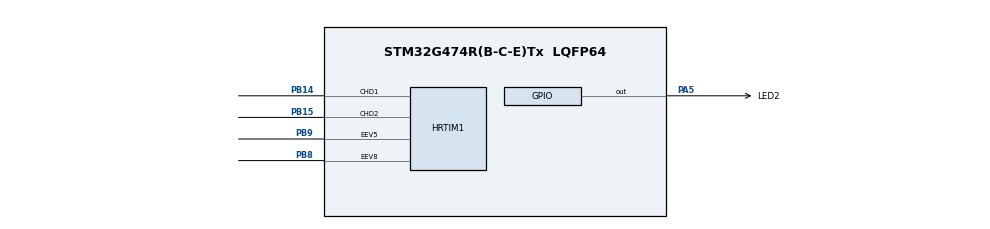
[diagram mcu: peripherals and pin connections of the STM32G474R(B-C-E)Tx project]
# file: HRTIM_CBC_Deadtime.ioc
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HRTIM1.ADCTrigger_Id1=__NULL
HRTIM1.ADCTrigger_Id10=__NULL
HRTIM1.ADCTrigger_Id2=__NULL
HRTIM1.ADCTrigger_Id3=__NULL
HRTIM1.ADCTrigger_Id4=__NULL
HRTIM1.ADCTrigger_Id5=__NULL
HRTIM1.ADCTrigger_Id6=__NULL
HRTIM1.ADCTrigger_Id7=__NULL
HRTIM1.ADCTrigger_Id8=__NULL
HRTIM1.ADCTrigger_Id9=__NULL
HRTIM1.AutoDelayedMode2-Output_TD1TD2=HRTIM_AUTODELAYEDMODE_AUTODELAYED_TIMEOUTCMP3
HRTIM1.AutoDelayedMode4-Output_TD1TD2=HRTIM_AUTODELAYEDMODE_AUTODELAYED_NOTIMEOUT
HRTIM1.BurstDMAconfig-Output_TD1TD2=__NULL
HRTIM1.BurstMode-Output_TD1TD2=HRTIM_TIMERBURSTMODE_MAINTAINCLOCK
HRTIM1.BurstModeEntryDelayed1-Output_TD1TD2=HRTIM_OUTPUTBURSTMODEENTRY_REGULAR
HRTIM1.BurstModeEntryDelayed2-Output_TD1TD2=HRTIM_OUTPUTBURSTMODEENTRY_REGULAR
HRTIM1.CaptureUnit1-Output_TD1TD2=HRTIM_CAPTUREUNIT_1
HRTIM1.CaptureUnit2-Output_TD1TD2=HRTIM_CAPTUREUNIT_2
HRTIM1.ChopperModeEnable1-Output_TD1TD2=HRTIM_OUTPUTCHOPPERMODE_DISABLED
HRTIM1.ChopperModeEnable2-Output_TD1TD2=HRTIM_OUTPUTCHOPPERMODE_DISABLED
HRTIM1.ChopperModeconfig-Output_TD1TD2=__NULL
HRTIM1.CompareUnit1-Output_TD1TD2=HRTIM_COMPAREUNIT_1
HRTIM1.CompareUnit2-Output_TD1TD2=HRTIM_COMPAREUNIT_2
HRTIM1.CompareUnit3-Output_TD1TD2=HRTIM_COMPAREUNIT_3
HRTIM1.CompareUnit4-Output_TD1TD2=HRTIM_COMPAREUNIT_4
HRTIM1.CompareValue1-Output_TD1TD2=DEADTIME
HRTIM1.CompareValue2-Output_TD1TD2=DEADTIME
HRTIM1.CompareValue4-Output_TD1TD2=DEADTIME
HRTIM1.Configuration_TD=Waveform
HRTIM1.DACSynchro-Output_TD1TD2=HRTIM_DACSYNC_NONE
HRTIM1.DeadTimeInsertion-Output_TD1TD2=HRTIM_TIMDEADTIMEINSERTION_DISABLED
HRTIM1.Deadtimeconfig-Output_TD1TD2=__NULL
HRTIM1.DelayedProtectionMode-Output_TD1TD2=HRTIM_TIMER_D_E_DELAYEDPROTECTION_DISABLED
HRTIM1.DualChannelDacEnableFake_TD-Output_TD1TD2=HRTIM_TIMER_DCDE_DISABLED
HRTIM1.Enable=HRTIM_BURSTMODECTL_DISABLED
HRTIM1.Event1-Output_TD1TD2=__NULL
HRTIM1.Event10-Output_TD1TD2=__NULL
HRTIM1.Event2-Output_TD1TD2=__NULL
HRTIM1.Event3-Output_TD1TD2=__NULL
HRTIM1.Event4-Output_TD1TD2=__NULL
HRTIM1.Event5-Output_TD1TD2=__NULL
HRTIM1.Event6-Output_TD1TD2=__NULL
HRTIM1.Event7-Output_TD1TD2=__NULL
HRTIM1.Event8-Output_TD1TD2=HRTIM_EVENT_8
HRTIM1.Event9-Output_TD1TD2=__NULL
HRTIM1.EventEnableA-Output_TD1TD2=__NULL
HRTIM1.EventPrescaler=HRTIM_EVENTPRESCALER_DIV1
HRTIM1.Event_EEV1=__NULL
HRTIM1.Event_EEV10=__NULL
HRTIM1.Event_EEV2=__NULL
HRTIM1.Event_EEV3=__NULL
HRTIM1.Event_EEV4=__NULL
HRTIM1.Event_EEV5=HRTIM_EVENT_5
HRTIM1.Event_EEV6=__NULL
HRTIM1.Event_EEV7=__NULL
HRTIM1.Event_EEV8=HRTIM_EVENT_8
HRTIM1.Event_EEV9=__NULL
HRTIM1.FastMode_EEV5=HRTIM_EVENTFASTMODE_DISABLE
HRTIM1.FaultLevel1-Output_TD1TD2=HRTIM_OUTPUTFAULTLEVEL_NONE
HRTIM1.FaultLevel2-Output_TD1TD2=HRTIM_OUTPUTFAULTLEVEL_NONE
HRTIM1.FaultLock-Output_TD1TD2=HRTIM_TIMFAULTLOCK_READWRITE
HRTIM1.Fault_Line1=__NULL
HRTIM1.Fault_Line2=__NULL
HRTIM1.Fault_Line3=__NULL
HRTIM1.Fault_Line4=__NULL
HRTIM1.Fault_Line5=__NULL
HRTIM1.Fault_Line6=__NULL
HRTIM1.Filter8-Output_TD1TD2=HRTIM_TIMEEVFLT_BLANKINGCMP1
HRTIM1.Filter_EEV8=HRTIM_EVENTFILTER_NONE
HRTIM1.GreaterCMP1_TD=HRTIM_TIMERGTCMP1_EQUAL
HRTIM1.GreaterCMP3_TD=HRTIM_TIMERGTCMP3_EQUAL
HRTIM1.HRTIMInterruptResquests1=HRTIM_IT_NONE
HRTIM1.HRTIMInterruptResquests2=HRTIM_IT_NONE
HRTIM1.HRTIMInterruptResquests3=HRTIM_IT_NONE
HRTIM1.HRTIMInterruptResquests4=HRTIM_IT_NONE
HRTIM1.HRTIMInterruptResquests5=HRTIM_IT_NONE
HRTIM1.HRTIMInterruptResquests6=HRTIM_IT_NONE
HRTIM1.HRTIMInterruptResquests7=HRTIM_IT_NONE
HRTIM1.HRTIMInterruptResquests8=HRTIM_IT_NONE
HRTIM1.HRTIMInterruptResquests9=HRTIM_IT_NONE
HRTIM1.IdleLevel1-Output_TD1TD2=HRTIM_OUTPUTIDLELEVEL_INACTIVE
HRTIM1.IdleLevel2-Output_TD1TD2=HRTIM_OUTPUTIDLELEVEL_INACTIVE
HRTIM1.IdleMode1-Output_TD1TD2=HRTIM_OUTPUTIDLEMODE_NONE
HRTIM1.IdleMode2-Output_TD1TD2=HRTIM_OUTPUTIDLEMODE_NONE
HRTIM1.InterleavedMode-Output_TD1TD2=HRTIM_INTERLEAVED_MODE_DISABLED
HRTIM1.InterruptRequests1-Output_TD1TD2=HRTIM_TIM_IT_REP
HRTIM1.Latch8-Output_TD1TD2=HRTIM_TIMEVENTLATCH_ENABLED
HRTIM1.ModeTimeBase-Output_TD1TD2=HRTIM_MODE_CONTINUOUS
HRTIM1.NumberDMARequests_TD=0
HRTIM1.NumberFaultEnable-Output_TD1TD2=0
HRTIM1.NumberInterruptRequests-Output_TD1TD2=1
HRTIM1.NumberResetSource1-Output_TD1TD2=3
HRTIM1.NumberResetSource2_TD=3
HRTIM1.NumberResetTrigger-Output_TD1TD2=0
HRTIM1.NumberSetSource1-Output_TD1TD2=1
HRTIM1.NumberSetSource2_TD=1
HRTIM1.NumberTriggerSource_Captureconfig1-Output_TD1TD2=1
HRTIM1.NumberTriggerSource_Captureconfig2-Output_TD1TD2=1
HRTIM1.NumberUpdateTrigger-Output_TD1TD2=0
HRTIM1.Output1-Output_TD1TD2=HRTIM_OUTPUT_TD1
HRTIM1.Output2-Output_TD1TD2=HRTIM_OUTPUT_TD2
HRTIM1.Periode_TD=TIMD_PERIOD
HRTIM1.Polarity1-Output_TD1TD2=HRTIM_OUTPUTPOLARITY_HIGH
HRTIM1.Polarity2-Output_TD1TD2=HRTIM_OUTPUTPOLARITY_HIGH
HRTIM1.Polarity_EEV5=HRTIM_EVENTPOLARITY_HIGH
HRTIM1.Polarity_EEV8=HRTIM_EVENTPOLARITY_HIGH
HRTIM1.PreloadEnable-Output_TD1TD2=HRTIM_PRELOAD_ENABLED
HRTIM1.PushPull-Output_TD1TD2=HRTIM_TIMPUSHPULLMODE_DISABLED
HRTIM1.ReSyncUpdate-Output_TD1TD2=HRTIM_TIMERESYNC_UPDATE_UNCONDITIONAL
HRTIM1.RepetitionCounter-Output_TD1TD2=0x02
HRTIM1.RepetitionUpdate-Output_TD1TD2=HRTIM_UPDATEONREPETITION_ENABLED
HRTIM1.ResetOnSync-Output_TD1TD2=HRTIM_SYNCRESET_DISABLED
HRTIM1.ResetOutput1_Source1-Output_TD1TD2=HRTIM_OUTPUTRESET_TIMCMP3
HRTIM1.ResetOutput1_Source2-Output_TD1TD2=HRTIM_OUTPUTRESET_EEV_5
HRTIM1.ResetOutput1_Source3-Output_TD1TD2=HRTIM_OUTPUTRESET_EEV_8
HRTIM1.ResetOutput2_Source1-Output_TD1TD2=HRTIM_OUTPUTRESET_TIMCMP4
HRTIM1.ResetOutput2_Source2-Output_TD1TD2=HRTIM_OUTPUTRESET_TIMPER
HRTIM1.ResetOutput2_Source3-Output_TD1TD2=HRTIM_OUTPUTRESET_EEV_5
HRTIM1.ResetUpdate-Output_TD1TD2=HRTIM_TIMUPDATEONRESET_DISABLED
HRTIM1.Sensitivity_EEV5=HRTIM_EVENTSENSITIVITY_LEVEL
HRTIM1.Sensitivity_EEV8=HRTIM_EVENTSENSITIVITY_BOTHEDGES
HRTIM1.SetOutput1_Source1-Output_TD1TD2=HRTIM_OUTPUTSET_TIMCMP1
HRTIM1.SetOutput2_Source1-Output_TD1TD2=HRTIM_OUTPUTSET_TIMCMP2
HRTIM1.Source_EEV5=HRTIM_EEV5SRC_GPIO
HRTIM1.Source_EEV8=HRTIM_EEV8SRC_GPIO
HRTIM1.StartOnSync-Output_TD1TD2=HRTIM_SYNCSTART_DISABLED
HRTIM1.SwapD=__NULL
HRTIM1.SyncOptions=HRTIM_SYNCOPTION_NONE
HRTIM1.TimerIdx-Output_TD1TD2=HRTIM_TIMERINDEX_TIMER_D
HRTIM1.TrigHalf_TD=HRTIM_TIMERTRIGHALF_DISABLED
HRTIM1.TriggerCapture1_Source1-Output_TD1TD2=HRTIM_CAPTURETRIGGER_EEV_8
HRTIM1.TriggerCapture2_Source1-Output_TD1TD2=HRTIM_CAPTURETRIGGER_EEV_8
HRTIM1.UpDownMode-Output_TD1TD2=HRTIM_TIMERUPDOWNMODE_UP
HRTIM1.UpdateGating-Output_TD1TD2=HRTIM_UPDATEGATING_INDEPENDENT
Mcu.Family=STM32G4
Mcu.Name=STM32G474R(B-C-E)Tx
Mcu.Package=LQFP64
Mcu.UserConstants=HRTIM_INPUT_CLOCK,170000000;TIMD_PWM_FREQ,100000;DEADTIME_IN_NS,100
NVIC.HRTIM1_TIMD_IRQn=true\:0\:0\:false\:false\:true\:true\:true\:true
NVIC.PriorityGroup=NVIC_PRIORITYGROUP_4
PA13.GPIO_Label=T_SWDIO
PA13.Mode=Serial_Wire
PA13.Signal=SYS_JTMS-SWDIO
PA14.GPIO_Label=T_SWCLK
PA14.Mode=Serial_Wire
PA14.Signal=SYS_JTCK-SWCLK
PA5.GPIO_Label=LED2
PA5.Signal=GPIO_Output
PB14.Mode=Output_TD1TD2
PB14.Signal=HRTIM1_CHD1
PB15.Mode=Output_TD1TD2
PB15.Signal=HRTIM1_CHD2
PB3.GPIO_Label=T_SWO
PB3.Signal=SYS_JTDO-SWO
PB8-BOOT0.Mode=External_Evt_enable8
PB8-BOOT0.Signal=HRTIM1_EEV8
PB9.Mode=External_Evt_enable5
PB9.Signal=HRTIM1_EEV5
PF0-OSC_IN.Mode=HSE-External-Oscillator
PF0-OSC_IN.Signal=RCC_OSC_IN
PF1-OSC_OUT.Mode=HSE-External-Oscillator
PF1-OSC_OUT.Signal=RCC_OSC_OUT
ProjectManager.HeapSize=0x200
ProjectManager.StackSize=0x400
ProjectManager.TargetToolchain=EWARM V8.32
RCC.ADC12Freq_Value=170000000
RCC.ADC345Freq_Value=170000000
RCC.AHBFreq_Value=170000000
RCC.APB1Freq_Value=170000000
RCC.APB1TimFreq_Value=170000000
RCC.APB2Freq_Value=170000000
RCC.APB2TimFreq_Value=170000000
RCC.CortexFreq_Value=170000000
RCC.EXTERNAL_CLOCK_VALUE=12288000
RCC.HCLKFreq_Value=170000000
RCC.HSE_VALUE=24000000
RCC.HSI48_VALUE=48000000
RCC.HSI_VALUE=16000000
RCC.LSE_VALUE=32768
RCC.PLLM=RCC_PLLM_DIV6
RCC.PLLN=85
RCC.PLLSourceVirtual=RCC_PLLSOURCE_HSE
RCC.SYSCLKFreq_VALUE=170000000
RCC.SYSCLKSource=RCC_SYSCLKSOURCE_PLLCLK
RCC.USBFreq_Value=170000000
RCC.VCOOutputFreq_Value=340000000
VP_SYS_VS_DBSignals.Mode=DisableDeadBatterySignals
board=custom

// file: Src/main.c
/* USER CODE BEGIN Header */
/**
  ******************************************************************************
  * @file           : main.c
  * @brief          : Main program body
  ******************************************************************************
  * @attention
  *
  * Copyright (c) 2019 STMicroelectronics.
  * All rights reserved.
  *
  * This software is licensed under terms that can be found in the LICENSE file
  * in the root directory of this software component.
  * If no LICENSE file comes with this software, it is provided AS-IS.
  *
  ******************************************************************************
  */
/* USER CODE END Header */
#include "main.h"

/* USER CODE BEGIN PD */
/* Formula below works for PWM frequency > 83kHz (with prescaler ratio = 1) */
#define TIMD_PERIOD ((uint16_t)((((uint64_t)HRTIM_INPUT_CLOCK) * 32) / TIMD_PWM_FREQ))

#define DEADTIME ((uint16_t)(((uint64_t)HRTIM_INPUT_CLOCK * 32 * DEADTIME_IN_NS) / 1000000000))

/* USER CODE END PD */

void SystemClock_Config(void);
static void MX_GPIO_Init(void);
static void MX_HRTIM1_Init(void);

int main(void)
{

  /* MCU Configuration--------------------------------------------------------*/

  /* Reset of all peripherals, Initializes the Flash interface and the Systick. */
  LL_APB2_GRP1_EnableClock(LL_APB2_GRP1_PERIPH_SYSCFG);
  LL_APB1_GRP1_EnableClock(LL_APB1_GRP1_PERIPH_PWR);

  /* System interrupt init*/
  NVIC_SetPriorityGrouping(NVIC_PRIORITYGROUP_4);

  /** Disable the internal Pull-Up in Dead Battery pins of UCPD peripheral
  */
  LL_PWR_DisableUCPDDeadBattery();

  /* Configure the system clock */
  SystemClock_Config();

  /* USER CODE BEGIN SysInit */
  LL_Init1msTick(170000000);
  /* USER CODE END SysInit */

  /* Initialize all configured peripherals */
  MX_GPIO_Init();
  MX_HRTIM1_Init();
  /* USER CODE BEGIN 2 */

  /* Start the timer and enable the outputs */
  LL_HRTIM_EnableIT_REP(HRTIM1, LL_HRTIM_TIMER_D);
  LL_HRTIM_TIM_CounterEnable(HRTIM1, LL_HRTIM_TIMER_D);
  LL_HRTIM_EnableOutput(HRTIM1, LL_HRTIM_OUTPUT_TD1);
  LL_HRTIM_EnableOutput(HRTIM1, LL_HRTIM_OUTPUT_TD2);

  /* USER CODE END 2 */

  /* Infinite loop */
  while (1)
  {

    /* USER CODE BEGIN 3 */

    /* Toggle the Nucleo board's LED2 at 10Hz */
    LL_GPIO_TogglePin(LED2_GPIO_Port, LED2_Pin);
    LL_mDelay(100);

  }
  /* USER CODE END 3 */
}

void SystemClock_Config(void)
{
  LL_FLASH_SetLatency(LL_FLASH_LATENCY_4);
  while(LL_FLASH_GetLatency() != LL_FLASH_LATENCY_4)
  {
  }
  LL_PWR_EnableRange1BoostMode();
  LL_RCC_HSE_Enable();
   /* Wait till HSE is ready */
  while(LL_RCC_HSE_IsReady() != 1)
  {
  }

  LL_RCC_PLL_ConfigDomain_SYS(LL_RCC_PLLSOURCE_HSE, LL_RCC_PLLM_DIV_6, 85, LL_RCC_PLLR_DIV_2);
  LL_RCC_PLL_EnableDomain_SYS();
  LL_RCC_PLL_Enable();
   /* Wait till PLL is ready */
  while(LL_RCC_PLL_IsReady() != 1)
  {
  }

  LL_RCC_SetSysClkSource(LL_RCC_SYS_CLKSOURCE_PLL);
  LL_RCC_SetAHBPrescaler(LL_RCC_SYSCLK_DIV_2);
   /* Wait till System clock is ready */
  while(LL_RCC_GetSysClkSource() != LL_RCC_SYS_CLKSOURCE_STATUS_PLL)
  {
  }

  /* Insure 1us transition state at intermediate medium speed clock*/
  for (__IO uint32_t i = (170 >> 1); i !=0; i--);

  /* Set AHB prescaler*/
  LL_RCC_SetAHBPrescaler(LL_RCC_SYSCLK_DIV_1);
  LL_RCC_SetAPB1Prescaler(LL_RCC_APB1_DIV_1);
  LL_RCC_SetAPB2Prescaler(LL_RCC_APB2_DIV_1);

  LL_Init1msTick(170000000);

  LL_SetSystemCoreClock(170000000);
}

static void MX_HRTIM1_Init(void)
{

  LL_GPIO_InitTypeDef GPIO_InitStruct = {0};

  /* Peripheral clock enable */
  LL_APB2_GRP1_EnableClock(LL_APB2_GRP1_PERIPH_HRTIM1);

  LL_AHB2_GRP1_EnableClock(LL_AHB2_GRP1_PERIPH_GPIOB);
  /**HRTIM1 GPIO Configuration
  PB8-BOOT0   ------> HRTIM1_EEV8
  PB9   ------> HRTIM1_EEV5
  */
  GPIO_InitStruct.Pin = LL_GPIO_PIN_8;
  GPIO_InitStruct.Mode = LL_GPIO_MODE_ALTERNATE;
  GPIO_InitStruct.Speed = LL_GPIO_SPEED_FREQ_LOW;
  GPIO_InitStruct.OutputType = LL_GPIO_OUTPUT_PUSHPULL;
  GPIO_InitStruct.Pull = LL_GPIO_PULL_NO;
  GPIO_InitStruct.Alternate = LL_GPIO_AF_13;
  LL_GPIO_Init(GPIOB, &GPIO_InitStruct);

  GPIO_InitStruct.Pin = LL_GPIO_PIN_9;
  GPIO_InitStruct.Mode = LL_GPIO_MODE_ALTERNATE;
  GPIO_InitStruct.Speed = LL_GPIO_SPEED_FREQ_LOW;
  GPIO_InitStruct.OutputType = LL_GPIO_OUTPUT_PUSHPULL;
  GPIO_InitStruct.Pull = LL_GPIO_PULL_NO;
  GPIO_InitStruct.Alternate = LL_GPIO_AF_13;
  LL_GPIO_Init(GPIOB, &GPIO_InitStruct);

  /* HRTIM1 interrupt Init */
  NVIC_SetPriority(HRTIM1_TIMD_IRQn, NVIC_EncodePriority(NVIC_GetPriorityGrouping(),0, 0));
  NVIC_EnableIRQ(HRTIM1_TIMD_IRQn);

  LL_HRTIM_ConfigDLLCalibration(HRTIM1, LL_HRTIM_DLLCALIBRATION_MODE_CONTINUOUS, LL_HRTIM_DLLCALIBRATION_RATE_3);

  /* Poll for DLL end of calibration */
#if (USE_TIMEOUT == 1)
  uint32_t Timeout = 10; /* Timeout Initialization */
#endif  /*USE_TIMEOUT*/

  while(LL_HRTIM_IsActiveFlag_DLLRDY(HRTIM1) == RESET){
#if (USE_TIMEOUT == 1)
    if (LL_SYSTICK_IsActiveCounterFlag())  /* Check Systick counter flag to decrement the time-out value */
    {
        if(Timeout-- == 0)
        {
          Error_Handler();  /* error management */
        }
    }
#endif  /* USE_TIMEOUT */
  }

  LL_HRTIM_EE_SetPrescaler(HRTIM1, LL_HRTIM_EE_PRESCALER_DIV1);
  LL_HRTIM_EE_SetSrc(HRTIM1, LL_HRTIM_EVENT_5, LL_HRTIM_EEV5SRC_GPIO);
  LL_HRTIM_EE_SetPolarity(HRTIM1, LL_HRTIM_EVENT_5, LL_HRTIM_EE_POLARITY_HIGH);
  LL_HRTIM_EE_SetSensitivity(HRTIM1, LL_HRTIM_EVENT_5, LL_HRTIM_EE_SENSITIVITY_LEVEL);
  LL_HRTIM_EE_SetFastMode(HRTIM1, LL_HRTIM_EVENT_5, LL_HRTIM_EE_FASTMODE_DISABLE);
  LL_HRTIM_EE_SetSrc(HRTIM1, LL_HRTIM_EVENT_8, LL_HRTIM_EEV8SRC_GPIO);
  LL_HRTIM_EE_SetPolarity(HRTIM1, LL_HRTIM_EVENT_8, LL_HRTIM_EE_POLARITY_HIGH);
  LL_HRTIM_EE_SetSensitivity(HRTIM1, LL_HRTIM_EVENT_8, LL_HRTIM_EE_SENSITIVITY_BOTHEDGES);
  LL_HRTIM_EE_SetFilter(HRTIM1, LL_HRTIM_EVENT_8, LL_HRTIM_EE_FILTER_NONE);
  LL_HRTIM_TIM_SetPrescaler(HRTIM1, LL_HRTIM_TIMER_D, LL_HRTIM_PRESCALERRATIO_MUL32);
  LL_HRTIM_TIM_SetCounterMode(HRTIM1, LL_HRTIM_TIMER_D, LL_HRTIM_MODE_CONTINUOUS);
  LL_HRTIM_TIM_SetPeriod(HRTIM1, LL_HRTIM_TIMER_D, TIMD_PERIOD);
  LL_HRTIM_TIM_SetRepetition(HRTIM1, LL_HRTIM_TIMER_D, 0x02);
  LL_HRTIM_TIM_SetUpdateGating(HRTIM1, LL_HRTIM_TIMER_D, LL_HRTIM_UPDATEGATING_INDEPENDENT);
  LL_HRTIM_TIM_SetCountingMode(HRTIM1, LL_HRTIM_TIMER_D, LL_HRTIM_COUNTING_MODE_UP);
  LL_HRTIM_TIM_SetTriggeredHalfMode(HRTIM1, LL_HRTIM_TIMER_D, LL_HRTIM_TRIGHALF_DISABLED);
  LL_HRTIM_TIM_SetComp1Mode(HRTIM1, LL_HRTIM_TIMER_D, LL_HRTIM_GTCMP1_EQUAL);
  LL_HRTIM_TIM_SetComp3Mode(HRTIM1, LL_HRTIM_TIMER_D, LL_HRTIM_GTCMP3_EQUAL);
  LL_HRTIM_TIM_SetDACTrig(HRTIM1, LL_HRTIM_TIMER_D, LL_HRTIM_DACTRIG_NONE);
  LL_HRTIM_TIM_DisableHalfMode(HRTIM1, LL_HRTIM_TIMER_D);
  LL_HRTIM_TIM_SetInterleavedMode(HRTIM1, LL_HRTIM_TIMER_D, LL_HRTIM_INTERLEAVED_MODE_DISABLED);
  LL_HRTIM_TIM_DisableStartOnSync(HRTIM1, LL_HRTIM_TIMER_D);
  LL_HRTIM_TIM_DisableResetOnSync(HRTIM1, LL_HRTIM_TIMER_D);
  LL_HRTIM_TIM_EnablePreload(HRTIM1, LL_HRTIM_TIMER_D);
  LL_HRTIM_TIM_SetUpdateTrig(HRTIM1, LL_HRTIM_TIMER_D, LL_HRTIM_UPDATETRIG_NONE|LL_HRTIM_UPDATETRIG_REPETITION);
  LL_HRTIM_TIM_SetResetTrig(HRTIM1, LL_HRTIM_TIMER_D, LL_HRTIM_RESETTRIG_NONE);
  LL_HRTIM_TIM_DisablePushPullMode(HRTIM1, LL_HRTIM_TIMER_D);
  LL_HRTIM_TIM_DisableDeadTime(HRTIM1, LL_HRTIM_TIMER_D);
  LL_HRTIM_TIM_SetBurstModeOption(HRTIM1, LL_HRTIM_TIMER_D, LL_HRTIM_BURSTMODE_MAINTAINCLOCK);
  LL_HRTIM_ForceUpdate(HRTIM1, LL_HRTIM_TIMER_D);
  LL_HRTIM_TIM_DisableResyncUpdate(HRTIM1, LL_HRTIM_TIMER_D);
  LL_HRTIM_TIM_SetCompare1(HRTIM1, LL_HRTIM_TIMER_D, DEADTIME);
  LL_HRTIM_TIM_SetCompareMode(HRTIM1, LL_HRTIM_TIMER_D, LL_HRTIM_COMPAREUNIT_2, LL_HRTIM_COMPAREMODE_DELAY_CMP3);
  LL_HRTIM_TIM_SetCompare2(HRTIM1, LL_HRTIM_TIMER_D, DEADTIME);
  LL_HRTIM_TIM_SetCompare3(HRTIM1, LL_HRTIM_TIMER_D, 0x0000);
  LL_HRTIM_TIM_SetCompare4(HRTIM1, LL_HRTIM_TIMER_D, DEADTIME);
  LL_HRTIM_TIM_SetCompareMode(HRTIM1, LL_HRTIM_TIMER_D, LL_HRTIM_COMPAREUNIT_4, LL_HRTIM_COMPAREMODE_DELAY_NOTIMEOUT);
  LL_HRTIM_TIM_SetCaptureTrig(HRTIM1, LL_HRTIM_TIMER_D, LL_HRTIM_CAPTUREUNIT_1, LL_HRTIM_CAPTURETRIG_EEV_8);
  LL_HRTIM_TIM_SetCaptureTrig(HRTIM1, LL_HRTIM_TIMER_D, LL_HRTIM_CAPTUREUNIT_2, LL_HRTIM_CAPTURETRIG_EEV_8);
  LL_HRTIM_TIM_SetEventFilter(HRTIM1, LL_HRTIM_TIMER_D, LL_HRTIM_EVENT_8, LL_HRTIM_EEFLTR_BLANKINGCMP1);
  LL_HRTIM_TIM_SetEventLatchStatus(HRTIM1, LL_HRTIM_TIMER_D, LL_HRTIM_EVENT_8, LL_HRTIM_EELATCH_ENABLED);
  LL_HRTIM_OUT_SetPolarity(HRTIM1, LL_HRTIM_OUTPUT_TD1, LL_HRTIM_OUT_POSITIVE_POLARITY);
  LL_HRTIM_OUT_SetOutputSetSrc(HRTIM1, LL_HRTIM_OUTPUT_TD1, LL_HRTIM_OUTPUTSET_TIMCMP1);
  LL_HRTIM_OUT_SetOutputResetSrc(HRTIM1, LL_HRTIM_OUTPUT_TD1, LL_HRTIM_OUTPUTRESET_TIMCMP3|LL_HRTIM_OUTPUTRESET_EEV_5
                              |LL_HRTIM_OUTPUTRESET_EEV_8);
  LL_HRTIM_OUT_SetIdleMode(HRTIM1, LL_HRTIM_OUTPUT_TD1, LL_HRTIM_OUT_NO_IDLE);
  LL_HRTIM_OUT_SetIdleLevel(HRTIM1, LL_HRTIM_OUTPUT_TD1, LL_HRTIM_OUT_IDLELEVEL_INACTIVE);
  LL_HRTIM_OUT_SetFaultState(HRTIM1, LL_HRTIM_OUTPUT_TD1, LL_HRTIM_OUT_FAULTSTATE_NO_ACTION);
  LL_HRTIM_OUT_SetChopperMode(HRTIM1, LL_HRTIM_OUTPUT_TD1, LL_HRTIM_OUT_CHOPPERMODE_DISABLED);
  LL_HRTIM_OUT_SetPolarity(HRTIM1, LL_HRTIM_OUTPUT_TD2, LL_HRTIM_OUT_POSITIVE_POLARITY);
  LL_HRTIM_OUT_SetOutputSetSrc(HRTIM1, LL_HRTIM_OUTPUT_TD2, LL_HRTIM_OUTPUTSET_TIMCMP2);
  LL_HRTIM_OUT_SetOutputResetSrc(HRTIM1, LL_HRTIM_OUTPUT_TD2, LL_HRTIM_OUTPUTRESET_TIMCMP4|LL_HRTIM_OUTPUTRESET_TIMPER
                              |LL_HRTIM_OUTPUTRESET_EEV_5);
  LL_HRTIM_OUT_SetIdleMode(HRTIM1, LL_HRTIM_OUTPUT_TD2, LL_HRTIM_OUT_NO_IDLE);
  LL_HRTIM_OUT_SetIdleLevel(HRTIM1, LL_HRTIM_OUTPUT_TD2, LL_HRTIM_OUT_IDLELEVEL_INACTIVE);
  LL_HRTIM_OUT_SetFaultState(HRTIM1, LL_HRTIM_OUTPUT_TD2, LL_HRTIM_OUT_FAULTSTATE_NO_ACTION);
  LL_HRTIM_OUT_SetChopperMode(HRTIM1, LL_HRTIM_OUTPUT_TD2, LL_HRTIM_OUT_CHOPPERMODE_DISABLED);
  /* USER CODE BEGIN HRTIM1_Init 2 */

  /* This is to override a limitation in CubeMX v5.2.0 */
  GPIO_InitStruct.Speed = LL_GPIO_SPEED_FREQ_VERY_HIGH;

  /* USER CODE END HRTIM1_Init 2 */
  LL_AHB2_GRP1_EnableClock(LL_AHB2_GRP1_PERIPH_GPIOB);
  /**HRTIM1 GPIO Configuration
  PB14   ------> HRTIM1_CHD1
  PB15   ------> HRTIM1_CHD2
  */
  GPIO_InitStruct.Pin = LL_GPIO_PIN_14;
  GPIO_InitStruct.Mode = LL_GPIO_MODE_ALTERNATE;
  GPIO_InitStruct.Speed = LL_GPIO_SPEED_FREQ_VERY_HIGH;
  GPIO_InitStruct.OutputType = LL_GPIO_OUTPUT_PUSHPULL;
  GPIO_InitStruct.Pull = LL_GPIO_PULL_NO;
  GPIO_InitStruct.Alternate = LL_GPIO_AF_13;
  LL_GPIO_Init(GPIOB, &GPIO_InitStruct);

  GPIO_InitStruct.Pin = LL_GPIO_PIN_15;
  GPIO_InitStruct.Mode = LL_GPIO_MODE_ALTERNATE;
  GPIO_InitStruct.Speed = LL_GPIO_SPEED_FREQ_VERY_HIGH;
  GPIO_InitStruct.OutputType = LL_GPIO_OUTPUT_PUSHPULL;
  GPIO_InitStruct.Pull = LL_GPIO_PULL_NO;
  GPIO_InitStruct.Alternate = LL_GPIO_AF_13;
  LL_GPIO_Init(GPIOB, &GPIO_InitStruct);

}

static void MX_GPIO_Init(void)
{
  LL_GPIO_InitTypeDef GPIO_InitStruct = {0};

  /* GPIO Ports Clock Enable */
  LL_AHB2_GRP1_EnableClock(LL_AHB2_GRP1_PERIPH_GPIOF);
  LL_AHB2_GRP1_EnableClock(LL_AHB2_GRP1_PERIPH_GPIOA);
  LL_AHB2_GRP1_EnableClock(LL_AHB2_GRP1_PERIPH_GPIOB);

  /**/
  LL_GPIO_ResetOutputPin(LED2_GPIO_Port, LED2_Pin);

  /**/
  GPIO_InitStruct.Pin = LED2_Pin;
  GPIO_InitStruct.Mode = LL_GPIO_MODE_OUTPUT;
  GPIO_InitStruct.Speed = LL_GPIO_SPEED_FREQ_LOW;
  GPIO_InitStruct.OutputType = LL_GPIO_OUTPUT_PUSHPULL;
  GPIO_InitStruct.Pull = LL_GPIO_PULL_NO;
  LL_GPIO_Init(LED2_GPIO_Port, &GPIO_InitStruct);

}

void Error_Handler(void)
{
  /* USER CODE BEGIN Error_Handler_Debug */
  /* Turn LED2 on */
  LL_GPIO_SetOutputPin(LED2_GPIO_Port, LED2_Pin);

  /* User can add his own implementation to report the HAL error return state */
  while(1)
  {
  }
  /* USER CODE END Error_Handler_Debug */
}

#ifdef  USE_FULL_ASSERT
/**
  * @brief  Reports the name of the source file and the source line number
  *         where the assert_param error has occurred.
  * @param  file: pointer to the source file name
  * @param  line: assert_param error line source number
  * @retval None
  */
void assert_failed(uint8_t *file, uint32_t line)
{
  /* USER CODE BEGIN 6 */
  while(1);
  /* USER CODE END 6 */
}
#endif /* USE_FULL_ASSERT */
